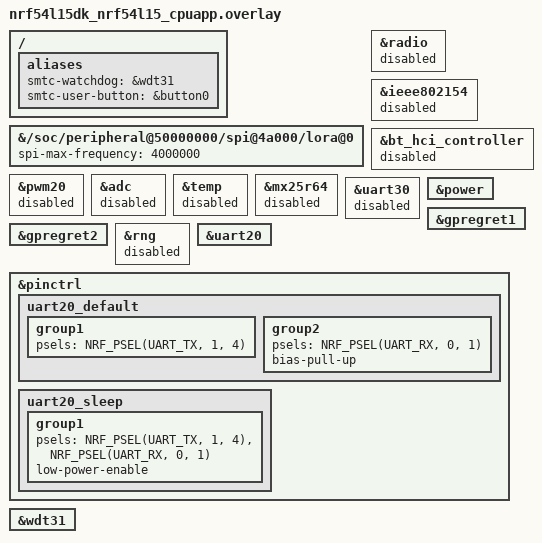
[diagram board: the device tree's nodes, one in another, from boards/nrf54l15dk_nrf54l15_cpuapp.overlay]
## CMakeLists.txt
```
# Copyright (c) 2024 Semtech Corporation
# SPDX-License-Identifier: Apache-2.0

cmake_minimum_required(VERSION 3.13.1)

find_package(Zephyr REQUIRED HINTS $ENV{ZEPHYR_BASE})
project(ranging_demo)

target_compile_definitions(app PRIVATE DISABLE_RANGING_LOG)

target_sources(app PRIVATE
  ${CMAKE_CURRENT_SOURCE_DIR}/src/main.c
  ${CMAKE_CURRENT_SOURCE_DIR}/src/app_ranging_result_output.c
  ${CMAKE_CURRENT_SOURCE_DIR}/src/oled_display.c
  ${ZEPHYR_USP_MODULE_DIR}/examples/main_examples/ranging_demo/app_ranging_hopping.c
)

zephyr_include_directories(
  ${CMAKE_CURRENT_SOURCE_DIR}/src
  ${ZEPHYR_USP_MODULE_DIR}/examples/main_examples/ranging_demo
)
```

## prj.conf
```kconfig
# Copyright (c) 2024 Semtech Corporation
# SPDX-License-Identifier: Apache-2.0

# --------------------------- General configuration ---------------------------

CONFIG_USE_SEGGER_RTT=n

# heap size
CONFIG_HEAP_MEM_POOL_SIZE=4096

CONFIG_LOG=y

CONFIG_TEST_RANDOM_GENERATOR=y

CONFIG_PM_DEVICE=y

CONFIG_WATCHDOG=n

CONFIG_FLASH=y

CONFIG_I2C=y

# ------------------------------ Transceiver driver ----------------------------

CONFIG_LORA_BASICS_MODEM_DRIVERS=y
# We chose to disable intermediate thread between IRQ and USP RAC Thread to make timestamping is as fast as possible
CONFIG_LORA_BASICS_MODEM_DRIVERS_EVENT_TRIGGER_NO_THREAD=y
#CONFIG_LORA_BASICS_MODEM_DRIVERS_EVENT_TRIGGER_GLOBAL_THREAD=n
#CONFIG_LORA_BASICS_MODEM_DRIVERS_EVENT_TRIGGER_OWN_THREAD=n

# ------------------------------ USP -----------------------------


CONFIG_USP=y
CONFIG_USP_MAIN_THREAD=y

#CONFIG_USP_LOG_LEVEL_DBG=y

CONFIG_LOG_BUFFER_SIZE=4096

# CONFIG_CLOCK_CONTROL=y
# CONFIG_CLOCK_CONTROL_NRF=y

CONFIG_MAIN_STACK_SIZE=4096
CONFIG_STACK_SENTINEL=y

# Debug stack (à enlever en production)
CONFIG_THREAD_STACK_INFO=y
CONFIG_STACK_SENTINEL=y
CONFIG_THREAD_MONITOR=y
CONFIG_THREAD_NAME=y

# Threads are cooperative (non-preemptive) to simplify critical section management and avoid complex synchronization.
# This approach may reduce reactivity when ISR (interrupt service routines) are triggered (low optimization)
# The USP RAC thread is assigned a higher priority: it will execute immediately once the Main thread yields or blocks, ensuring prompt handling of USP RAC-related tasks.
# The Main thread has a lower priority: it runs only when the USP RAC thread is idle or waiting
CONFIG_MAIN_THREAD_PRIORITY=-2
CONFIG_USP_MAIN_THREAD_PRIORITY=-4

# Threads are preemptive: a thread with a higher priority can interrupt (preempt) a lower priority thread at any time.
# USP RAC thread has higher priority (1): it will preempt the main thread immediately whenever it is ready to run (ISR/Timer), ensuring low latency and fast response for USP RAC-related tasks.
# Main thread has lower priority (3): it runs only when the USP RAC thread is not active, yielding CPU time to the more urgent USP RAC operations automatically.
# This priority scheme allows responsive multitasking with guaranteed preemption based on thread priority.
# CONFIG_MAIN_THREAD_PRIORITY=3
# CONFIG_USP_MAIN_THREAD_PRIORITY=1
# CONFIG_USP_THREADS_MUTEXES=y

#
# Priority Inversion : In case of multiple threads with different priorities, consider the modification of existing priorities and mutex use, or use Zephyr capabilities :
# CONFIG_KERNEL_MEM_POOL=y
# CONFIG_MUTEX_PRIORITY_INHERITANCE=y
# CONFIG_PRIORITY_CEILING=y

# Only one thread
# CONFIG_USP_MAIN_THREAD_PRIORITY=0


# ------------------------------ Debug -----------------------------
CONFIG_DEBUG=y
CONFIG_NO_OPTIMIZATIONS=y
CONFIG_DEBUG_OPTIMIZATIONS=y
CONFIG_DEBUG_THREAD_INFO=y
CONFIG_DCACHE=n
```

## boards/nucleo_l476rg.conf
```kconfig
# Copyright (c) 2024 Semtech Corporation
# SPDX-License-Identifier: Apache-2.0

# ------------------------------ NUCLEO L476RG CLOCK DRIFT -----------------------------
CONFIG_CORTEX_M_SYSTICK=n
CONFIG_STM32_LPTIM_TIMER=y
CONFIG_CLOCK_CONTROL=y
CONFIG_PM=y
CONFIG_RESET=y

CONFIG_IDLE_STACK_SIZE=512
```

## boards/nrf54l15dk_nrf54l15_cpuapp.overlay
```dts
// /*
//  * Copyright (c) 2024 Semtech Corporation
//  *
//  * SPDX-License-Identifier: Apache-2.0
//  */

/ {
	aliases {
		smtc-watchdog = &wdt31;
		smtc-user-button = &button0;
	};
};

// Set SPI freq @4MHz
&{/soc/peripheral@50000000/spi@4a000/lora@0} {
	spi-max-frequency = < 4000000 >;
};

&radio {
	status = "disabled";
};

&ieee802154 {
	status = "disabled";
};

&bt_hci_controller {
	status = "disabled";
};

&pwm20 {
	status = "disabled";
};

&adc {
	status = "disabled";
};

&temp {
	status = "disabled";
};

&mx25r64 {
	status = "disabled";
};


// &rng_hci {
	//     status = "disabled";
// };

&uart30 {
	status = "disabled";
};

// &clock {
	//     status = "disabled"; //For some reason, disabling it increases power consumption
// };

&power {
	status = "okay";
};

&gpregret1 {
	status = "okay";
};

&gpregret2 {
	status = "okay";
};

&rng {
	status = "disabled";
};

// &spi00 {
	//     status = "disabled";
// };


&uart20 {
	status = "okay";
	// disable-rx; //Disabling RX allows a gain of ~200µA, totally disabling uart allows another gain of ~200µA
	// /delete-property/ hw-flow-control;
};

&pinctrl {
	uart20_default: uart20_default {
		group1 {
			psels = <NRF_PSEL(UART_TX, 1, 4)>
			// ,<NRF_PSEL(UART_RTS, 0, 2)>
			;
		};
		group2 {
			psels = <NRF_PSEL(UART_RX, 0, 1)> //DIO9 is mapped on RX
			// ,<NRF_PSEL(UART_CTS, 0, 3)>
			;
			bias-pull-up;
		};
	};

	uart20_sleep: uart20_sleep {
		group1 {
			psels = <NRF_PSEL(UART_TX, 1, 4)>,
					<NRF_PSEL(UART_RX, 0, 1)>
					// ,<NRF_PSEL(UART_RTS, 0, 2)>
					// ,<NRF_PSEL(UART_CTS, 0, 3)>
					;
			low-power-enable;
		};
	};
};

&wdt31 {
	status = "okay";
};
```

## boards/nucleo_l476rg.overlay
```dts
/*
 * Copyright (c) 2024 Semtech Corporation
 *
 * SPDX-License-Identifier: Apache-2.0
 */

/ {
	aliases {
		smtc-watchdog = &iwdg;
		smtc-user-button = &user_button;
	};
};

&spi3 {
	status = "disabled";
};

&iwdg {
	status = "disabled";
};

&arduino_spi {
	/delete-property/ overrun-character;
};

// Remove continuous warning log in ranging demo ( i2c_ll_stm32_common: I2C pinctrl sleep state not available)
&pinctrl {
	i2c1_scl_pb8_sleep: i2c1_scl_pb8_sleep {
		pinmux = <STM32_PINMUX('B', 8, ANALOG)>;
	};

	i2c1_sda_pb9_sleep: i2c1_sda_pb9_sleep {
		pinmux = <STM32_PINMUX('B', 9, ANALOG)>;
	};
};

&arduino_i2c {
	/delete-property/ zephyr,concat-buf-size;
	pinctrl-1 = <&i2c1_scl_pb8_sleep &i2c1_sda_pb9_sleep>;
	pinctrl-names = "default", "sleep";
};

&i2c3 {
	status = "disabled";
};

&lptim1 {
	clocks = <&rcc STM32_CLOCK_BUS_APB1 0x80000000>,
		 <&rcc STM32_SRC_LSE LPTIM1_SEL(3)>;
	status = "okay";
};
```

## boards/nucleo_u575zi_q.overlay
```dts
/*
 * Copyright (c) 2024 Semtech Corporation
 *
 * SPDX-License-Identifier: Apache-2.0
 */

/ {
	aliases {
		smtc-watchdog = &iwdg;
		smtc-user-button = &user_button;
	};
};

// i2c1 is used as arduino_i2c for the LoRa Expansion Board screen (It is status = "okay")

&i2c2 {
	status = "disabled";
};

&lptim1 {
	status = "disabled";
};

&timers3 {
	status = "disabled";
};

&timers4 {
	status = "disabled";
};

&dac1 {
	status = "disabled";
};

&adc1 {
	status = "disabled";
};

&adc4 {
	status = "disabled";
};

&fdcan1 {
	status = "disabled";
};

&usbotg_fs {
	status = "disabled";
};

&usart2 {
	status = "disabled";
};

&iwdg {
	status = "disabled";
};

&wwdg {
	status = "disabled";
};

&arduino_i2c {
        /delete-property/ zephyr,concat-buf-size;
};

&arduino_spi {
	/delete-property/ overrun-character;
};
```

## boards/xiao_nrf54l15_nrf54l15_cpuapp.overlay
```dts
// /*
//  * Copyright (c) 2024 Semtech Corporation
//  *
//  * SPDX-License-Identifier: Apache-2.0
//  */

/ {
	aliases {
		smtc-watchdog = &wdt31;
		smtc-user-button = &usr_btn;
	};
};

&xiao_serial {
	status = "disabled";
};

&i2c22 {
	status = "okay";
};

&i2c30 {
	status = "disabled";
};

&adc {
	status = "disabled";
};

&wdt31 {
	status = "okay";
};

// Override xiao_nrf54l15 default configuration for USP applications
// Disable boot-on for RF switch regulators to save power

&rfsw_ctl {
	/delete-property/ regulator-boot-on;
};

&rfsw_pwr {
	/delete-property/ regulator-boot-on;
};

&vbat_pwr {
	/delete-property/ regulator-boot-on;
};
```

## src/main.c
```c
/**
 * @file      main.c
 *
 * @brief     Application main
 *
 * The Clear BSD License
 * Copyright Semtech Corporation 2025. All rights reserved.
 *
 * Redistribution and use in source and binary forms, with or without
 * modification, are permitted (subject to the limitations in the disclaimer
 * below) provided that the following conditions are met:
 *     * Redistributions of source code must retain the above copyright
 *       notice, this list of conditions and the following disclaimer.
 *     * Redistributions in binary form must reproduce the above copyright
 *       notice, this list of conditions and the following disclaimer in the
 *       documentation and/or other materials provided with the distribution.
 *     * Neither the name of the Semtech corporation nor the
 *       names of its contributors may be used to endorse or promote products
 *       derived from this software without specific prior written permission.
 *
 * NO EXPRESS OR IMPLIED LICENSES TO ANY PARTY'S PATENT RIGHTS ARE GRANTED BY
 * THIS LICENSE. THIS SOFTWARE IS PROVIDED BY THE COPYRIGHT HOLDERS AND
 * CONTRIBUTORS "AS IS" AND ANY EXPRESS OR IMPLIED WARRANTIES, INCLUDING, BUT
 * NOT LIMITED TO, THE IMPLIED WARRANTIES OF MERCHANTABILITY AND FITNESS FOR A
 * PARTICULAR PURPOSE ARE DISCLAIMED. IN NO EVENT SHALL SEMTECH CORPORATION BE
 * LIABLE FOR ANY DIRECT, INDIRECT, INCIDENTAL, SPECIAL, EXEMPLARY, OR
 * CONSEQUENTIAL DAMAGES (INCLUDING, BUT NOT LIMITED TO, PROCUREMENT OF
 * SUBSTITUTE GOODS OR SERVICES; LOSS OF USE, DATA, OR PROFITS; OR BUSINESS
 * INTERRUPTION) HOWEVER CAUSED AND ON ANY THEORY OF LIABILITY, WHETHER IN
 * CONTRACT, STRICT LIABILITY, OR TORT (INCLUDING NEGLIGENCE OR OTHERWISE)
 * ARISING IN ANY WAY OUT OF THE USE OF THIS SOFTWARE, EVEN IF ADVISED OF THE
 * POSSIBILITY OF SUCH DAMAGE.
 */

#include <stdint.h>   // C99 types
#include <stdbool.h>  // bool type

#include <zephyr/kernel.h>
#include <zephyr/drivers/gpio.h>

#include <zephyr/kernel.h>
#include <zephyr/drivers/gpio.h>
#include <zephyr/devicetree.h>
#include <zephyr/device.h>
#include <zephyr/logging/log.h>

#include <apps_configuration.h>
#include <app_ranging_hopping.h>
#include <app_ranging_result_output.h>
#include <main_ranging_demo.h>

#define SMTC_HAL_DBG_TRACE_C
#include <smtc_hal_dbg_trace.h>
#include <smtc_hal_led.h>
#include <smtc_zephyr_usp_api.h>
#include <smtc_sw_platform_helper.h>

#include <zephyr/lorawan_lbm/lorawan_hal_init.h>
#include <smtc_core_hal.h>

#if DT_HAS_CHOSEN( zephyr_display )
#include "oled_display.h"
#endif

/*
 * -----------------------------------------------------------------------------
 * --- PRIVATE MACROS-----------------------------------------------------------
 */

LOG_MODULE_REGISTER( ranging_demo, LOG_LEVEL_INF );

/*
 * -----------------------------------------------------------------------------
 * --- PRIVATE CONSTANTS -------------------------------------------------------
 */

/**
 * @brief Watchdog counter reload value during sleep (The period must be lower than MCU watchdog period (here 32s))
 */
#define WATCHDOG_RELOAD_PERIOD_MS 20000

/**
 * @brief Blue user button or BUTTON 1 on nrf52840-dk
 */

#define USER_BUTTON_NODE DT_ALIAS( smtc_user_button )
#if !DT_NODE_HAS_STATUS( USER_BUTTON_NODE, okay )
#error "Unsupported board: smtc-user-button devicetree alias is not defined"
#endif
static const struct gpio_dt_spec button = GPIO_DT_SPEC_GET_OR( USER_BUTTON_NODE, gpios, { 0 } );
static struct gpio_callback      button_cb_data;

/*
 * -----------------------------------------------------------------------------
 * --- PRIVATE TYPES -----------------------------------------------------------
 */
static volatile bool user_button_is_press = false;  // Flag for button status

/*
 * -----------------------------------------------------------------------------
 * --- PRIVATE VARIABLES -------------------------------------------------------
 * Defines application-level variables for manager/subordinate mode,
 * periodic transmission configuration, and payload buffer.
 */

// Set is_manager based on compile-time macro (see main_ranging_demo.h)
#if defined( RANGING_DEVICE_MODE ) && ( RANGING_DEVICE_MODE == RANGING_DEVICE_MODE_MANAGER )
static const bool is_manager = true;
#elif defined( RANGING_DEVICE_MODE ) && ( RANGING_DEVICE_MODE == RANGING_DEVICE_MODE_SUBORDINATE )
static const bool is_manager = false;
#else
#error Application must define RANGING_DEVICE_MODE
#endif

static smtc_rac_context_t* periodic_tx_config      = NULL;   // Context for periodic uplink
static uint8_t             periodic_tx_payload[33] = { 0 };  // Payload buffer for periodic uplink
static uint8_t             periodic_tx_handle;               // Radio access handle for periodic uplink

char* bw_str[] = { "007K", "010K", "015K", "020K", "031K", "041K",   "062K",  "125K",
                   "200K", "250K", "400K", "500K", "800K", "1000_K", "1600_K" };

/*
 * -----------------------------------------------------------------------------
 * --- PRIVATE FUNCTIONS DECLARATION -------------------------------------------
 * Prototypes for internal helper functions.
 */

/**
 * @brief User callback for button EXTI
 *
 * @param context Define by the user at the init
 */
static void user_button_callback( const void* context );

/**
 * @brief Configure User Button
 *
 */
static int configure_user_button( void );

static void periodic_tx_handle_callback( rp_status_t status );
static void periodic_tx_handle_start( void );
static void periodic_tx_handle_config( void );

static void results_callback( smtc_rac_radio_lora_params_t* radio_lora_params,
                              ranging_params_settings_t*    ranging_params_settings,
                              ranging_global_result_t* ranging_global_results, const char* region );

/*
 * -----------------------------------------------------------------------------
 * --- PUBLIC FUNCTIONS DEFINITION ---------------------------------------------
 */

/* A binary semaphore to notify the main LBM loop */
K_SEM_DEFINE( periodical_uplink_event_sem, 0, 1 );

/* for zephyr compat*/
void button_pressed( const struct device* dev, struct gpio_callback* cb, uint32_t pins )
{
    printk( "%s", __func__ );
    user_button_callback( dev );
}

int main( void )
{
    if( configure_user_button( ) != 0 )
    {
        LOG_ERR( "Issue when configuring user button, aborting\n" );
        return 1;
    }
#if DT_HAS_CHOSEN( zephyr_display )
    oled_display_init( );
    oled_cls( );
#endif

    SMTC_HAL_TRACE_INFO( "===== ranging and frequency hopping example =====\r\n" );

    SMTC_SW_PLATFORM_INIT( );
    SMTC_SW_PLATFORM_VOID( smtc_rac_init( ) );

    hal_led_init( );
    hal_led_set( HAL_LED_SCAN, true );
    if( is_manager == true )
    {
#if DT_HAS_CHOSEN( zephyr_display )
        oled_show_str( 4 * 30, 0, "M", 1 );
#endif
        hal_led_set( HAL_LED_TX, true );
        hal_led_set( HAL_LED_RX, false );
        SMTC_HAL_TRACE_INFO( "Running in ranging manager mode\n" );
        app_radio_ranging_params_init( is_manager, RAC_HIGH_PRIORITY );
        app_radio_ranging_set_user_callback( results_callback );
#if defined( CONTINUOUS_RANGING ) && ( CONTINUOUS_RANGING == true )
        start_ranging_exchange( 0, is_manager );
#endif
    }
    else
    {
#if DT_HAS_CHOSEN( zephyr_display )
        oled_show_str( 4 * 30, 0, "S", 1 );
        oled_show_str( 0, 2, "   Joining...", 2 );
#endif
        hal_led_set( HAL_LED_TX, false );
        hal_led_set( HAL_LED_RX, true );
        SMTC_HAL_TRACE_INFO( "Running in ranging subordinate mode\n" );
        app_radio_ranging_params_init( is_manager, RAC_HIGH_PRIORITY );
        app_radio_ranging_set_user_callback( results_callback );
        start_ranging_exchange( 0, is_manager );
    }
    // If periodic uplink is enabled, configure and start periodic transmissions
    if( PERIODIC_UPLINK_ENABLED == true )
    {
        periodic_tx_handle = SMTC_SW_PLATFORM( smtc_rac_open_radio( RAC_VERY_HIGH_PRIORITY ) );
        periodic_tx_config = smtc_rac_get_context( periodic_tx_handle );
        periodic_tx_config->scheduler_config.callback_post_radio_transaction = periodic_tx_handle_callback;
        periodic_tx_handle_config( );
        periodic_tx_handle_start( );
    }

    // Main application loop
    while( true )
    {
        // Check button
        if( user_button_is_press == true )
        {
            user_button_is_press = false;

            // Code to be added on button event
            start_ranging_exchange( 0, is_manager );
        }

#if !defined( CONFIG_USP_MAIN_THREAD )
        smtc_rac_run_engine( );
        if( smtc_rac_is_irq_flag_pending( ) )
        {
            continue;
        }
        // Allows waking up on radio event or push-button press
        struct k_sem* sems[] = { smtc_modem_hal_get_event_sem( ), &periodical_uplink_event_sem };
        ( void ) wait_on_sems( sems, 2, K_MSEC( WATCHDOG_RELOAD_PERIOD_MS ) );
#else
        if( user_button_is_press == false )
        {
            k_sem_take( &periodical_uplink_event_sem, K_MSEC( WATCHDOG_RELOAD_PERIOD_MS ) );
        }
#endif
    }
    return 0;
}

/*
 * -----------------------------------------------------------------------------
 * --- PRIVATE FUNCTIONS DEFINITION --------------------------------------------
 */

static int configure_user_button( void )
{
    int ret = 0;
    if( !gpio_is_ready_dt( &button ) )
    {
        printk( "Error: button device %s is not ready\n", button.port->name );
        return 1;
    }

    ret = gpio_pin_configure_dt( &button, GPIO_INPUT );
    if( ret != 0 )
    {
        printk( "Error %d: failed to configure %s pin %d\n", ret, button.port->name, button.pin );
        return 1;
    }

    ret = gpio_pin_interrupt_configure_dt( &button, GPIO_INT_EDGE_TO_ACTIVE );
    if( ret != 0 )
    {
        printk( "Error %d: failed to configure interrupt on %s pin %d\n", ret, button.port->name, button.pin );
        return 1;
    }

    gpio_init_callback( &button_cb_data, button_pressed, BIT( button.pin ) );
    gpio_add_callback( button.port, &button_cb_data );

    return 0;
}

static void user_button_callback( const void* context )
{
    LOG_INF( "Button pushed\n" );

    ( void ) context;  // Not used in the example - avoid warning

    static uint32_t last_press_timestamp_ms = 0;

    // Debounce the button press, avoid multiple triggers
    if( ( int32_t ) ( smtc_modem_hal_get_time_in_ms( ) - last_press_timestamp_ms ) > 500 )
    {
        last_press_timestamp_ms = smtc_modem_hal_get_time_in_ms( );
        user_button_is_press    = true;
    }
    // Wake up the main thread
    k_sem_give( &periodical_uplink_event_sem );
}

/**
 * @brief Callback for periodic uplink transmission.
 *
 * @param status Not used in this example.
 */
static void periodic_tx_handle_callback( rp_status_t status )
{
    UNUSED( status );
    periodic_tx_handle_start( );
}

/**
 * @brief Configures the periodic uplink transmission parameters.
 *
 * Sets up the radio parameters, payload, and scheduling for periodic transmissions.
 */
static void periodic_tx_handle_config( void )
{
    periodic_tx_config->modulation_type                                 = SMTC_RAC_MODULATION_LORA;
    periodic_tx_config->radio_params.lora.frequency_in_hz               = 868000000;
    periodic_tx_config->radio_params.lora.tx_power_in_dbm               = 14;
    periodic_tx_config->radio_params.lora.preamble_len_in_symb          = 8;
    periodic_tx_config->radio_params.lora.header_type                   = RAL_LORA_PKT_EXPLICIT;
    periodic_tx_config->radio_params.lora.invert_iq_is_on               = 0;
    periodic_tx_config->radio_params.lora.crc_is_on                     = 1;
    periodic_tx_config->radio_params.lora.sync_word                     = LORA_PUBLIC_NETWORK_SYNCWORD;
    periodic_tx_config->radio_params.lora.sf                            = RAL_LORA_SF12;
    periodic_tx_config->radio_params.lora.bw                            = RAL_LORA_BW_125_KHZ;
    periodic_tx_config->radio_params.lora.cr                            = RAL_LORA_CR_4_5;
    periodic_tx_config->radio_params.lora.is_tx                         = true;
    periodic_tx_config->smtc_rac_data_buffer_setup.tx_payload_buffer    = periodic_tx_payload;
    periodic_tx_config->radio_params.lora.tx_size                       = sizeof( periodic_tx_payload );
    periodic_tx_config->scheduler_config.scheduling                     = SMTC_RAC_ASAP_TRANSACTION;
    periodic_tx_config->scheduler_config.start_time_ms                  = smtc_modem_hal_get_time_in_ms( );
    periodic_tx_config->scheduler_config.callback_pre_radio_transaction = NULL;
}

/**
 * @brief Start the periodic uplink transmission.
 *
 * Schedules the next periodic uplink and sends the current payload.
 */
static void periodic_tx_handle_start( void )
{
    periodic_tx_config->scheduler_config.start_time_ms = smtc_modem_hal_get_time_in_ms( ) + TX_PERIODICITY_IN_MS;
    SMTC_SW_PLATFORM( smtc_rac_submit_radio_transaction( periodic_tx_handle ) );
    SMTC_HAL_TRACE_INFO( "Periodic tx done\n" );
}

static void results_callback( smtc_rac_radio_lora_params_t* radio_lora_params,
                              ranging_params_settings_t*    ranging_params_settings,
                              ranging_global_result_t* ranging_global_results, const char* region )
{
    app_ranging_radio_settings_output( radio_lora_params, ranging_params_settings );
    app_ranging_results_output( is_manager, ranging_global_results, RANGING_HOPPING_CHANNELS_MAX );

#if DT_HAS_CHOSEN( zephyr_display )
    uint8_t         output_str[16];
    static uint8_t  dash_x     = 0;
    static uint32_t loop_count = 0;
    char*           dots[]     = { ".   ", "..  ", "... ", "...." };

    oled_show_str( 4 * 24, 0, ( char* ) region, 1 );

    snprintf( output_str, 4, "%d", radio_lora_params->sf );
    oled_show_str( 0, 6, "SF:", 1 );
    oled_show_str( 4 * 6, 6, output_str, 1 );

    snprintf( output_str, 6, "%d ", ranging_global_results->rssi_value );
    oled_show_str( 4 * 16, 6, "RSSI:", 1 );
    oled_show_str( 4 * 26, 6, output_str, 1 );

    oled_show_str( 0, 7, "BW:", 1 );
    oled_show_str( 4 * 6, 7, bw_str[( int ) radio_lora_params->bw], 1 );

    snprintf( output_str, 6, "%d ", ranging_global_results->snr_value );
    oled_show_str( 4 * 16, 7, "SNR :", 1 );
    oled_show_str( 4 * 26, 7, output_str, 1 );

    if( is_manager == true )
    {
        if( dash_x >= 128 )
            dash_x = 0;

        if( dash_x == 0 )
        {
            oled_show_str( 0, 2, " -", 1 );
            oled_show_str( 31, 2, " ", 1 );
        }
        else
        {
            oled_show_str( dash_x, 2, " -", 1 );
        }
        dash_x += 8;

        oled_show_str( 0, 0, "Distance:", 2 );
        snprintf( output_str, 16, "   %d meters  ", ranging_global_results->rng_distance );
        oled_show_str( 0, 3, output_str, 2 );
    }
    else
    {
        loop_count++;
        if( loop_count == 1 )  // overwrite just once
            oled_show_str( 0, 2, "   Running   ", 2 );
        oled_show_str( 8 * 10, 2, dots[loop_count % 4], 2 );
    }
#endif
}

/* --- EOF ------------------------------------------------------------------ */
```

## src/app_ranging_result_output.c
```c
/**
 * @file      app_ranging_result_output.c
 *
 * @brief     Print the ranging results
 *
 * The Clear BSD License
 * Copyright Semtech Corporation 2025. All rights reserved.
 *
 * Redistribution and use in source and binary forms, with or without
 * modification, are permitted (subject to the limitations in the disclaimer
 * below) provided that the following conditions are met:
 *     * Redistributions of source code must retain the above copyright
 *       notice, this list of conditions and the following disclaimer.
 *     * Redistributions in binary form must reproduce the above copyright
 *       notice, this list of conditions and the following disclaimer in the
 *       documentation and/or other materials provided with the distribution.
 *     * Neither the name of the Semtech corporation nor the
 *       names of its contributors may be used to endorse or promote products
 *       derived from this software without specific prior written permission.
 *
 * NO EXPRESS OR IMPLIED LICENSES TO ANY PARTY'S PATENT RIGHTS ARE GRANTED BY
 * THIS LICENSE. THIS SOFTWARE IS PROVIDED BY THE COPYRIGHT HOLDERS AND
 * CONTRIBUTORS "AS IS" AND ANY EXPRESS OR IMPLIED WARRANTIES, INCLUDING, BUT
 * NOT LIMITED TO, THE IMPLIED WARRANTIES OF MERCHANTABILITY AND FITNESS FOR A
 * PARTICULAR PURPOSE ARE DISCLAIMED. IN NO EVENT SHALL SEMTECH CORPORATION BE
 * LIABLE FOR ANY DIRECT, INDIRECT, INCIDENTAL, SPECIAL, EXEMPLARY, OR
 * CONSEQUENTIAL DAMAGES (INCLUDING, BUT NOT LIMITED TO, PROCUREMENT OF
 * SUBSTITUTE GOODS OR SERVICES; LOSS OF USE, DATA, OR PROFITS; OR BUSINESS
 * INTERRUPTION) HOWEVER CAUSED AND ON ANY THEORY OF LIABILITY, WHETHER IN
 * CONTRACT, STRICT LIABILITY, OR TORT (INCLUDING NEGLIGENCE OR OTHERWISE)
 * ARISING IN ANY WAY OUT OF THE USE OF THIS SOFTWARE, EVEN IF ADVISED OF THE
 * POSSIBILITY OF SUCH DAMAGE.
 */

/*
 * -----------------------------------------------------------------------------
 * --- DEPENDENCIES ------------------------------------------------------------
 */
#include <stdio.h>
#include <stdlib.h>
#include <inttypes.h>

#include "smtc_rac_log.h"
#include "apps_configuration.h"
#include "smtc_hal_dbg_trace.h"
#include "app_ranging_result_output.h"

/*
 * -----------------------------------------------------------------------------
 * --- PRIVATE MACROS-----------------------------------------------------------
 */
#define RANGING_LOG_RESULT printf

/*
 * -----------------------------------------------------------------------------
 * --- PRIVATE CONSTANTS -------------------------------------------------------
 */

/*
 * -----------------------------------------------------------------------------
 * --- PRIVATE TYPES -----------------------------------------------------------
 */

/*
 * -----------------------------------------------------------------------------
 * --- PRIVATE VARIABLES -------------------------------------------------------
 */

/*
 * -----------------------------------------------------------------------------
 * --- PRIVATE FUNCTIONS DECLARATION -------------------------------------------
 */

/*
 * -----------------------------------------------------------------------------
 * --- PUBLIC FUNCTIONS DEFINITION ---------------------------------------------
 */

void app_ranging_radio_settings_output( smtc_rac_radio_lora_params_t* lora_settings,
                                        ranging_params_settings_t*    ranging_settings )
{
    RANGING_LOG_RESULT( "\r\n" );
    RANGING_LOG_RESULT( "{\r\n" );
    RANGING_LOG_RESULT( "\"SF\": \"%s\",\r\n", ral_lora_sf_to_str( lora_settings->sf ) );
    RANGING_LOG_RESULT( "\"BW\": \"%s\",\r\n", ral_lora_bw_to_str( lora_settings->bw ) );
}

void app_ranging_results_output( bool is_manager, ranging_global_result_t* result, int count )
{
    uint32_t freq;

    RANGING_LOG_RESULT( "\"ROLE\": \"%s\",\r\n", ( is_manager == true ) ? "MANAGER" : "SUBORDINATE" );
    RANGING_LOG_RESULT( "\"LoRa RSSI\": \"%d dBm\",\r\n", result->rssi_value );
    RANGING_LOG_RESULT( "\"LoRa SNR\": %d,\r\n", result->snr_value );

    if( result->cnt_packet_rx_ok == 0 )
    {
        RANGING_LOG_RESULT( "\"RngResult\": {\r\n\t\"Num\": %d\r\n\t}\r\n},\r\n", result->cnt_packet_rx_ok );
        return;
    }

    RANGING_LOG_RESULT( "\"RngResult\": {\r\n\t\"Num\": %d,\r\n\t\"Results\": [\r\n", result->cnt_packet_rx_ok );
    for( int i = 0; i < count; i++ )
    {
        if( result->rng_result[i].distance_m == 0 && result->rng_result[i].rssi == 0 )
            continue;

        // Get the channel frequency according to index
        freq = get_ranging_hopping_channels( i );

        RANGING_LOG_RESULT( "\t\t{\"FreqIndex\": \"%d\", ", i );
        RANGING_LOG_RESULT( "\"Freq\": \"%" PRIu32 ".%02" PRIu32 " MHz\", ", freq / 1000000, ( freq / 10000 ) % 100 );
        RANGING_LOG_RESULT( "\"RawDistance\": \"0x%08" PRIx32 "\", ", result->rng_result[i].raw_distance );
        RANGING_LOG_RESULT( "\"Distance\": \"%" PRId32 " m\", ", result->rng_result[i].distance_m );

        if( i < count - 1 )
        {
            RANGING_LOG_RESULT( "\"RSSI\": \"%d dBm\" },\r\n", result->rng_result[i].rssi );
        }
        else
        {
            RANGING_LOG_RESULT( "\"RSSI\": \"%d dBm\" }\r\n", result->rng_result[i].rssi );
        }
    }

    RANGING_LOG_RESULT( "\t\t],\r\n" );
    RANGING_LOG_RESULT( "\t\"DistanceRng\": \"%" PRId32 " m\",\r\n", result->rng_distance );
    RANGING_LOG_RESULT( "\t\"PER\": \"%d %%\"\r\n\t}\r\n", result->rng_per );
    RANGING_LOG_RESULT( "},\r\n" );
}

/*
 * -----------------------------------------------------------------------------
 * --- PRIVATE FUNCTION DEFINITIONS --------------------------------------------
 */

/* --- EOF ------------------------------------------------------------------ */
```

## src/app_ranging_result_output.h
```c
/**
 * @file      app_ranging_result_output.h
 *
 * @brief     Print the ranging results
 *
 * The Clear BSD License
 * Copyright Semtech Corporation 2024. All rights reserved.
 *
 * Redistribution and use in source and binary forms, with or without
 * modification, are permitted (subject to the limitations in the disclaimer
 * below) provided that the following conditions are met:
 *     * Redistributions of source code must retain the above copyright
 *       notice, this list of conditions and the following disclaimer.
 *     * Redistributions in binary form must reproduce the above copyright
 *       notice, this list of conditions and the following disclaimer in the
 *       documentation and/or other materials provided with the distribution.
 *     * Neither the name of the Semtech corporation nor the
 *       names of its contributors may be used to endorse or promote products
 *       derived from this software without specific prior written permission.
 *
 * NO EXPRESS OR IMPLIED LICENSES TO ANY PARTY'S PATENT RIGHTS ARE GRANTED BY
 * THIS LICENSE. THIS SOFTWARE IS PROVIDED BY THE COPYRIGHT HOLDERS AND
 * CONTRIBUTORS "AS IS" AND ANY EXPRESS OR IMPLIED WARRANTIES, INCLUDING, BUT
 * NOT LIMITED TO, THE IMPLIED WARRANTIES OF MERCHANTABILITY AND FITNESS FOR A
 * PARTICULAR PURPOSE ARE DISCLAIMED. IN NO EVENT SHALL SEMTECH CORPORATION BE
 * LIABLE FOR ANY DIRECT, INDIRECT, INCIDENTAL, SPECIAL, EXEMPLARY, OR
 * CONSEQUENTIAL DAMAGES (INCLUDING, BUT NOT LIMITED TO, PROCUREMENT OF
 * SUBSTITUTE GOODS OR SERVICES; LOSS OF USE, DATA, OR PROFITS; OR BUSINESS
 * INTERRUPTION) HOWEVER CAUSED AND ON ANY THEORY OF LIABILITY, WHETHER IN
 * CONTRACT, STRICT LIABILITY, OR TORT (INCLUDING NEGLIGENCE OR OTHERWISE)
 * ARISING IN ANY WAY OUT OF THE USE OF THIS SOFTWARE, EVEN IF ADVISED OF THE
 * POSSIBILITY OF SUCH DAMAGE.
 */

#ifndef APP_RANGING_RESULT_OUTPUT_H
#define APP_RANGING_RESULT_OUTPUT_H

#ifdef __cplusplus
extern "C" {
#endif

/*
 * -----------------------------------------------------------------------------
 * --- DEPENDENCIES ------------------------------------------------------------
 */
#include <stdint.h>

#include "app_ranging_hopping.h"

/*
 * -----------------------------------------------------------------------------
 * --- PUBLIC MACROS -----------------------------------------------------------
 */

/*
 * -----------------------------------------------------------------------------
 * --- PUBLIC CONSTANTS --------------------------------------------------------
 */

/*
 * -----------------------------------------------------------------------------
 * --- PUBLIC TYPES ------------------------------------------------------------
 */

/*
 * -----------------------------------------------------------------------------
 * --- PUBLIC FUNCTIONS PROTOTYPES ---------------------------------------------
 */

/*!
 * @brief Print the ranging settings
 *
 * @param [in] lora_settings  Pointer to the settings from application
 * @param [in] ranging_settings  Pointer to the settings from application
 */
void app_ranging_radio_settings_output( smtc_rac_radio_lora_params_t* lora_settings,
                                        ranging_params_settings_t*    ranging_settings );

/*!
 * @brief Print ranging results
 *
 * @param [in] is_manager  Indicates if the device is manager or subordinate
 * @param [in] result  Pointer to the ranging's results from application
 * @param [in] n  how many results available
 */
void app_ranging_results_output( bool is_manager, ranging_global_result_t* result, int count );

#ifdef __cplusplus
}
#endif

#endif  // APP_RANGING_RESULT_OUTPUT_H

/* --- EOF ------------------------------------------------------------------ */
```

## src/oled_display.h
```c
/**
 * @file      oled_display.h
 *
 * @brief     Library for OLED display
 *
 * The Clear BSD License
 * Copyright Semtech Corporation 2025. All rights reserved.
 *
 * Redistribution and use in source and binary forms, with or without
 * modification, are permitted (subject to the limitations in the disclaimer
 * below) provided that the following conditions are met:
 *     * Redistributions of source code must retain the above copyright
 *       notice, this list of conditions and the following disclaimer.
 *     * Redistributions in binary form must reproduce the above copyright
 *       notice, this list of conditions and the following disclaimer in the
 *       documentation and/or other materials provided with the distribution.
 *     * Neither the name of the Semtech corporation nor the
 *       names of its contributors may be used to endorse or promote products
 *       derived from this software without specific prior written permission.
 *
 * NO EXPRESS OR IMPLIED LICENSES TO ANY PARTY'S PATENT RIGHTS ARE GRANTED BY
 * THIS LICENSE. THIS SOFTWARE IS PROVIDED BY THE COPYRIGHT HOLDERS AND
 * CONTRIBUTORS "AS IS" AND ANY EXPRESS OR IMPLIED WARRANTIES, INCLUDING, BUT
 * NOT LIMITED TO, THE IMPLIED WARRANTIES OF MERCHANTABILITY AND FITNESS FOR A
 * PARTICULAR PURPOSE ARE DISCLAIMED. IN NO EVENT SHALL SEMTECH CORPORATION BE
 * LIABLE FOR ANY DIRECT, INDIRECT, INCIDENTAL, SPECIAL, EXEMPLARY, OR
 * CONSEQUENTIAL DAMAGES (INCLUDING, BUT NOT LIMITED TO, PROCUREMENT OF
 * SUBSTITUTE GOODS OR SERVICES; LOSS OF USE, DATA, OR PROFITS; OR BUSINESS
 * INTERRUPTION) HOWEVER CAUSED AND ON ANY THEORY OF LIABILITY, WHETHER IN
 * CONTRACT, STRICT LIABILITY, OR TORT (INCLUDING NEGLIGENCE OR OTHERWISE)
 * ARISING IN ANY WAY OUT OF THE USE OF THIS SOFTWARE, EVEN IF ADVISED OF THE
 * POSSIBILITY OF SUCH DAMAGE.
 */

#ifndef _OLED_DISPLAY_h_
#define _OLED_DISPLAY_h_

#include <stdint.h>

#define OLED_DISPLAY_WIDTH 128
#define OLED_DISPLAY_HEIGHT 64

void oled_display_init( void );
void led_mode( int mode, int intv, int duty_cycle );
void oled_init( void );
void oled_show_str( uint8_t x, uint8_t y, char ch[], uint8_t text_size );
void oled_off( void );
void oled_on( void );
void oled_cls( void );
void oled_fill( uint8_t fill_Data );
void oled_set_pos( uint8_t x, uint8_t y );
void oled_write_bitmap( uint8_t x, uint8_t y, uint8_t* bitmap, uint8_t width, uint8_t height );

#endif  // _OLED_DISPLAY_H_
```
